# STM32GBK1CBT6 register map
File version: 1.6
CPU: CM4 r0p1, little endian, MPU, FPU, 4 interrupt priority bits
Registers are 32-bit, read-write, reset 0x0 unless marked. A register's access mark holds for its fields unless they carry their own. Offsets are from the block's base; [hi:lo] are bit positions; {n}, {i} and the like mark numbered series.

## RCC — Reset and clock control
Base 0x40021000
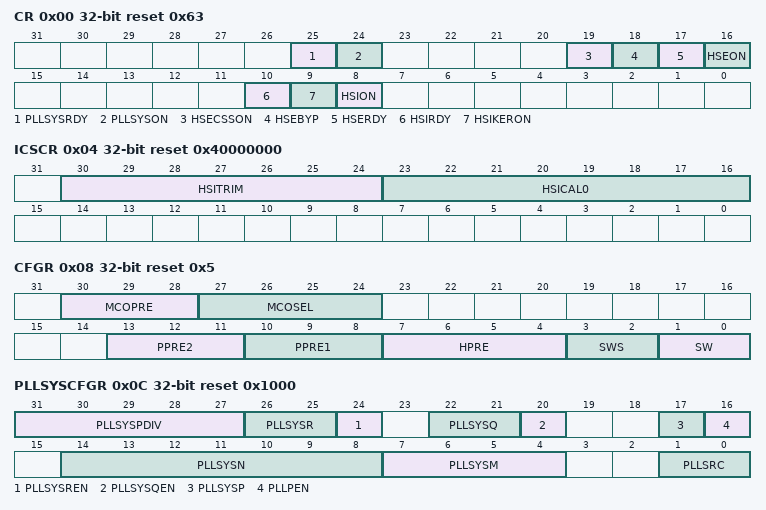
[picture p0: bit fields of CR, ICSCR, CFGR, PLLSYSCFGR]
0x00 CR access per field reset 0x63 — Clock control register
  [25] PLLSYSRDY ro — Main PLL clock ready flag
  [24] PLLSYSON rw — Main PLL enable
  [19] HSECSSON wo — Clock security system enable
  [18] HSEBYP rw — HSE crystal oscillator bypass
  [17] HSERDY ro — HSE clock ready flag
  [16] HSEON rw — HSE clock enable
  [10] HSIRDY ro — HSI clock ready flag
  [9] HSIKERON rw — HSI always enable for peripheral kernels
  [8] HSION rw — HSI clock enable
0x04 ICSCR access per field reset 0x40000000 — Internal clock sources calibration register
  [30:24] HSITRIM rw — Internal High Speed clock trimming
  [23:16] HSICAL0 ro — Internal High Speed clock Calibration
0x08 CFGR access per field reset 0x5 — Clock configuration register
  [30:28] MCOPRE rw — Microcontroller clock output prescaler
  [27:24] MCOSEL rw — Microcontroller clock output
  [13:11] PPRE2 rw — APB high-speed prescaler (APB2)
  [10:8] PPRE1 rw — PB low-speed prescaler (APB1)
  [7:4] HPRE rw — AHB prescaler
  [3:2] SWS ro — System clock switch status
  [1:0] SW rw — System clock switch
0x0C PLLSYSCFGR reset 0x1000 — PLL configuration register
  [31:27] PLLSYSPDIV — Main PLL division factor for PLLSAI2CLK
  [26:25] PLLSYSR — Main PLL division factor for PLLCLK (system clock)
  [24] PLLSYSREN — Main PLL PLLCLK output enable
  [22:21] PLLSYSQ — Main PLL division factor for PLLUSB1CLK(48 MHz clock)
  [20] PLLSYSQEN — Main PLL PLLUSB1CLK output enable
  [17] PLLSYSP — Main PLL division factor for PLLSAI3CLK (SAI1 and SAI2 clock)
  [16] PLLPEN — Main PLL PLLSAI3CLK output enable
  [14:8] PLLSYSN — Main PLL multiplication factor for VCO
  [7:4] PLLSYSM — Division factor for the main PLL and audio PLL (PLLSAI1 and PLLSAI2) input clock
  [1:0] PLLSRC — Main PLL, PLLSAI1 and PLLSAI2 entry clock source
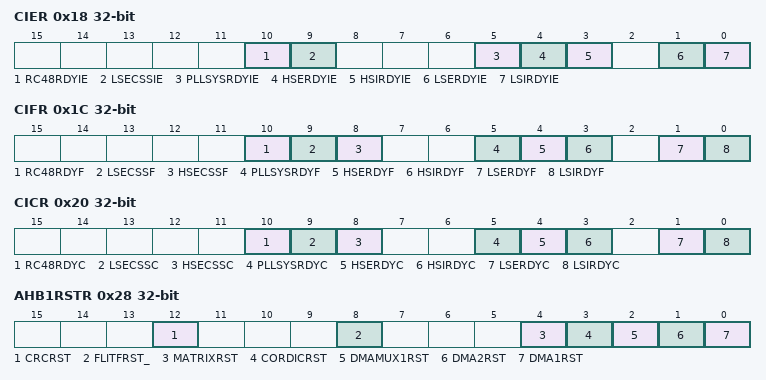
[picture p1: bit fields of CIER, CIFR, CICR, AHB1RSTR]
0x18 CIER — Clock interrupt enable register
  [10] RC48RDYIE — HSI48 ready interrupt enable
  [9] LSECSSIE — LSE clock security system interrupt enable
  [5] PLLSYSRDYIE — PLL ready interrupt enable
  [4] HSERDYIE — HSE ready interrupt enable
  [3] HSIRDYIE — HSI ready interrupt enable
  [1] LSERDYIE — LSE ready interrupt enable
  [0] LSIRDYIE — LSI ready interrupt enable
0x1C CIFR ro — Clock interrupt flag register
  [10] RC48RDYF — HSI48 ready interrupt flag
  [9] LSECSSF — LSE Clock security system interrupt flag
  [8] HSECSSF — Clock security system interrupt flag
  [5] PLLSYSRDYF — PLL ready interrupt flag
  [4] HSERDYF — HSE ready interrupt flag
  [3] HSIRDYF — HSI ready interrupt flag
  [1] LSERDYF — LSE ready interrupt flag
  [0] LSIRDYF — LSI ready interrupt flag
0x20 CICR wo — Clock interrupt clear register
  [10] RC48RDYC — HSI48 oscillator ready interrupt clear
  [9] LSECSSC — LSE Clock security system interrupt clear
  [8] HSECSSC — Clock security system interrupt clear
  [5] PLLSYSRDYC — PLL ready interrupt clear
  [4] HSERDYC — HSE ready interrupt clear
  [3] HSIRDYC — HSI ready interrupt clear
  [1] LSERDYC — LSE ready interrupt clear
  [0] LSIRDYC — LSI ready interrupt clear
0x28 AHB1RSTR — AHB1 peripheral reset register
  [12] CRCRST — CRC reset
  [8] FLITFRST_ — FLITF reset
  [4] MATRIXRST — MATRIX reset
  [3] CORDICRST — CORDIC reset
  [2] DMAMUX1RST — DMAMUXRST
  [1] DMA2RST — DMA2 reset
  [0] DMA1RST — DMA1 reset
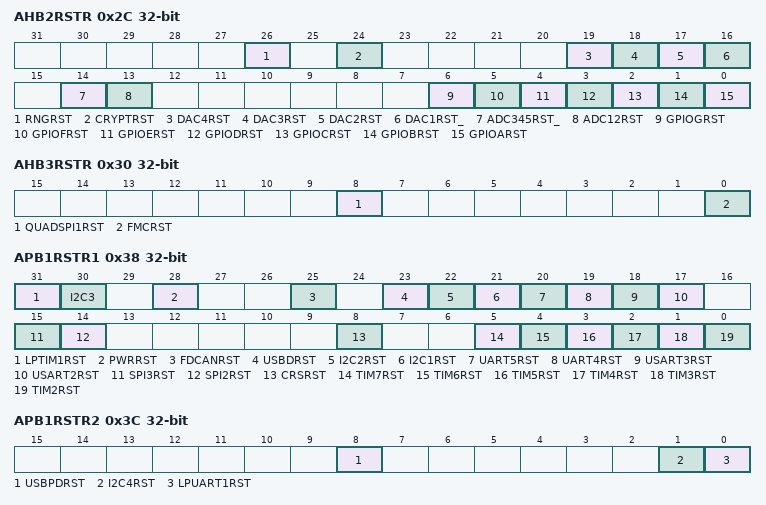
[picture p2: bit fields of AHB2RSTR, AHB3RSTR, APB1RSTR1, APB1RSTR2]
0x2C AHB2RSTR — AHB2 peripheral reset register
  [26] RNGRST — Random Number Generator module reset
  [24] CRYPTRST — Cryptography module reset
  [19] DAC4RST — DAC4 interface reset
  [18] DAC3RST — DAC3 interface reset
  [17] DAC2RST — DAC2 interface reset
  [16] DAC1RST_ — DAC1 interface reset
  [14] ADC345RST_ — SAR ADC345 interface reset
  [13] ADC12RST — ADC reset
  [6] GPIOGRST — IO port G reset
  [5] GPIOFRST — IO port F reset
  [4] GPIOERST — IO port E reset
  [3] GPIODRST — IO port D reset
  [2] GPIOCRST — IO port C reset
  [1] GPIOBRST — IO port B reset
  [0] GPIOARST — IO port A reset
0x30 AHB3RSTR — AHB3 peripheral reset register
  [8] QUADSPI1RST — Quad SPI 1 module reset
  [0] FMCRST — Flexible memory controller reset
0x38 APB1RSTR1 — APB1 peripheral reset register 1
  [31] LPTIM1RST — Low Power Timer 1 reset
  [30] I2C3 — I2C3 interface reset
  [28] PWRRST — Power interface reset
  [25] FDCANRST — FDCAN reset
  [23] USBDRST — USBD reset
  [22] I2C2RST — I2C2 reset
  [21] I2C1RST — I2C1 reset
  [20] UART5RST — UART5 reset
  [19] UART4RST — UART4 reset
  [18] USART3RST — USART3 reset
  [17] USART2RST — USART2 reset
  [15] SPI3RST — SPI3 reset
  [14] SPI2RST — SPI2 reset
  [8] CRSRST — Clock recovery system reset
  [5] TIM7RST — TIM7 timer reset
  [4] TIM6RST — TIM6 timer reset
  [3] TIM5RST — TIM5 timer reset
  [2] TIM4RST — TIM3 timer reset
  [1] TIM3RST — TIM3 timer reset
  [0] TIM2RST — TIM2 timer reset
0x3C APB1RSTR2 — APB1 peripheral reset register 2
  [8] USBPDRST — USBPD reset
  [1] I2C4RST — I2C4 reset
  [0] LPUART1RST — Low-power UART 1 reset
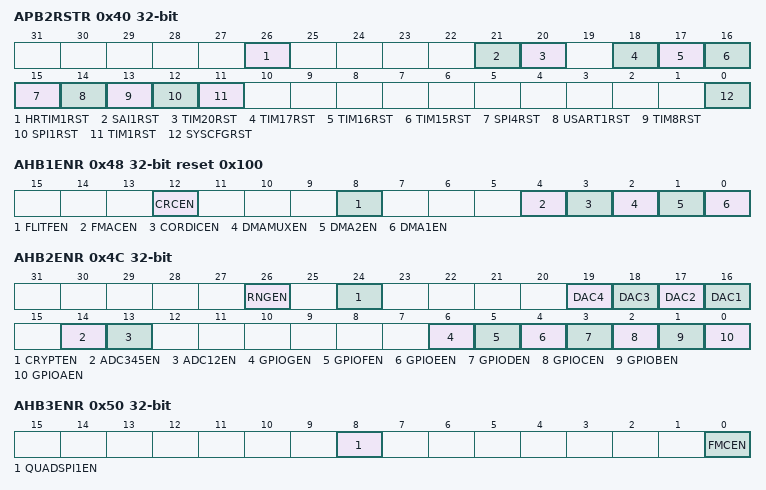
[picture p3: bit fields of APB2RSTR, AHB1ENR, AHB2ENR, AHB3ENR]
0x40 APB2RSTR — APB2 peripheral reset register
  [26] HRTIM1RST — HRTIMER reset
  [21] SAI1RST — Serial audio interface 1 (SAI1) reset
  [20] TIM20RST — Timer 20 reset
  [18] TIM17RST — TIM17 timer reset
  [17] TIM16RST — TIM16 timer reset
  [16] TIM15RST — TIM15 timer reset
  [15] SPI4RST — SPI 4 reset
  [14] USART1RST — USART1 reset
  [13] TIM8RST — TIM8 timer reset
  [12] SPI1RST — SPI1 reset
  [11] TIM1RST — TIM1 timer reset
  [0] SYSCFGRST — System configuration (SYSCFG) reset
0x48 AHB1ENR reset 0x100 — AHB1 peripheral clock enable register
  [12] CRCEN — CRC clock enable
  [8] FLITFEN — FLITF clock enable
  [4] FMACEN — FMAC clock enable
  [3] CORDICEN — CORDIC clock enable
  [2] DMAMUXEN — DMAMUX clock enable
  [1] DMA2EN — DMA2 clock enable
  [0] DMA1EN — DMA1 clock enable
0x4C AHB2ENR — AHB2 peripheral clock enable register
  [26] RNGEN — Random Number Generator clock enable
  [24] CRYPTEN — Cryptography clock enable
  [19] DAC4 — DAC4 clock enable
  [18] DAC3 — Random Number Generator clock enable
  [17] DAC2 — HASH clock enable
  [16] DAC1 — AES accelerator clock enable
  [14] ADC345EN — DCMI clock enable
  [13] ADC12EN — ADC clock enable
  [6] GPIOGEN — IO port G clock enable
  [5] GPIOFEN — IO port F clock enable
  [4] GPIOEEN — IO port E clock enable
  [3] GPIODEN — IO port D clock enable
  [2] GPIOCEN — IO port C clock enable
  [1] GPIOBEN — IO port B clock enable
  [0] GPIOAEN — IO port A clock enable
0x50 AHB3ENR — AHB3 peripheral clock enable register
  [8] QUADSPI1EN — Quad SPI 1 module clock enable
  [0] FMCEN — Flexible memory controller clock enable
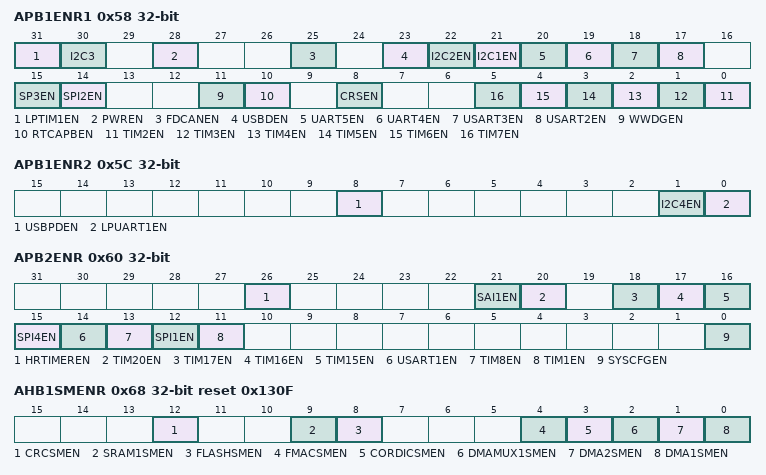
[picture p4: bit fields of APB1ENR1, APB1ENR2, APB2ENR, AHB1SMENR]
0x58 APB1ENR1
  [31] LPTIM1EN — Low power timer 1 clock enable
  [30] I2C3 — OPAMP interface clock enable
  [28] PWREN — Power interface clock enable
  [25] FDCANEN — FDCAN clock enable
  [23] USBDEN — USBDclock enable
  [22] I2C2EN — I2C2 clock enable
  [21] I2C1EN — I2C1 clock enable
  [20] UART5EN — UART5 clock enable
  [19] UART4EN — UART4 clock enable
  [18] USART3EN — USART3 clock enable
  [17] USART2EN — USART2 clock enable
  [15] SP3EN — SPI3 clock enable
  [14] SPI2EN — SPI2 clock enable
  [11] WWDGEN — Window watchdog clock enable
  [10] RTCAPBEN — RTC APB clock enable
  [8] CRSEN — CRSclock enable
  [n-2] TIM{n}EN (n=2..7) — TIM{n} timer clock enable
0x5C APB1ENR2 — APB1 peripheral clock enable register 2
  [8] USBPDEN — USBPD clock enable
  [1] I2C4EN — I2C4 clock enable
  [0] LPUART1EN — Low power UART 1 clock enable
0x60 APB2ENR
  [26] HRTIMEREN — HRTIMER clock enable
  [21] SAI1EN — SAI1 clock enable
  [20] TIM20EN — Timer 20 clock enable
  [18] TIM17EN — TIM17 timer clock enable
  [17] TIM16EN — TIM16 timer clock enable
  [16] TIM15EN — TIM15 timer clock enable
  [15] SPI4EN — SPI 4 clock enable
  [14] USART1EN — USART1clock enable
  [13] TIM8EN — TIM8 timer clock enable
  [12] SPI1EN — SPI1 clock enable
  [11] TIM1EN — TIM1 timer clock enable
  [0] SYSCFGEN — SYSCFG clock enable
0x68 AHB1SMENR reset 0x130F — AHB1 peripheral clocks enable in Sleep and Stop modes register
  [12] CRCSMEN
  [9] SRAM1SMEN — SRAM1 interface clocks enable during Sleep and Stop modes
  [8] FLASHSMEN — Flash memory interface clocks enable during Sleep and Stop modes
  [4] FMACSMEN — FMACSM clock enable
  [3] CORDICSMEN — CORDIC clock enable during sleep mode
  [2] DMAMUX1SMEN — DMAMUX clock enable during Sleep and Stop modes
  [1] DMA2SMEN — DMA2 clocks enable during Sleep and Stop modes
  [0] DMA1SMEN — DMA1 clocks enable during Sleep and Stop modes
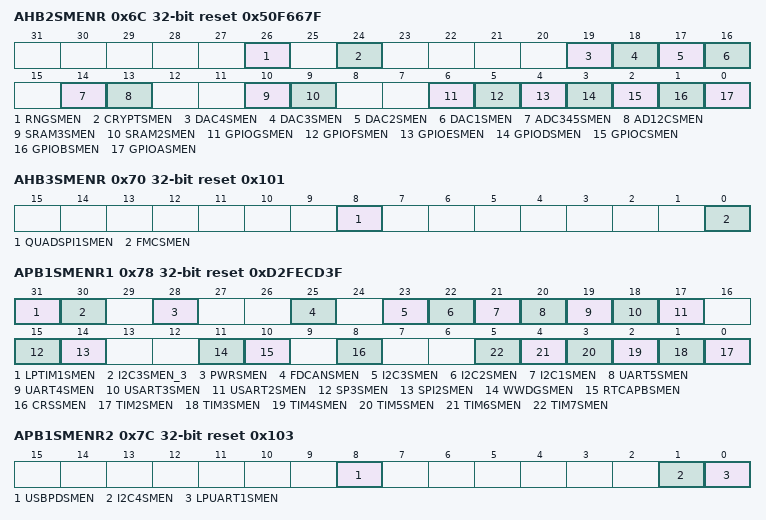
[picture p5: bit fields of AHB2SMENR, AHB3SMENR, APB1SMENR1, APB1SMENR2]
0x6C AHB2SMENR reset 0x50F667F — AHB2 peripheral clocks enable in Sleep and Stop modes register
  [26] RNGSMEN — Random Number Generator clock enable during sleep mode
  [24] CRYPTSMEN — Cryptography clock enable during sleep mode
  [19] DAC4SMEN — DAC4 clock enable during sleep mode
  [18] DAC3SMEN — DAC3 clock enable during sleep mode
  [17] DAC2SMEN — HASH clock enable during Sleep and Stop modes
  [16] DAC1SMEN — AES accelerator clocks enable during Sleep and Stop modes
  [14] ADC345SMEN — DCMI clock enable during Sleep and Stop modes
  [13] AD12CSMEN — ADC clocks enable during Sleep and Stop modes
  [10] SRAM3SMEN — SRAM2 interface clocks enable during Sleep and Stop modes
  [9] SRAM2SMEN — SRAM2 interface clocks enable during Sleep and Stop modes
  [6] GPIOGSMEN — IO port G clocks enable during Sleep and Stop modes
  [5] GPIOFSMEN — IO port F clocks enable during Sleep and Stop modes
  [4] GPIOESMEN — IO port E clocks enable during Sleep and Stop modes
  [3] GPIODSMEN — IO port D clocks enable during Sleep and Stop modes
  [2] GPIOCSMEN — IO port C clocks enable during Sleep and Stop modes
  [1] GPIOBSMEN — IO port B clocks enable during Sleep and Stop modes
  [0] GPIOASMEN — IO port A clocks enable during Sleep and Stop modes
0x70 AHB3SMENR reset 0x101 — AHB3 peripheral clocks enable in Sleep and Stop modes register
  [8] QUADSPI1SMEN — QUAD SPI 1 module clock enable during sleep mode
  [0] FMCSMEN — Flexible memory controller clocks enable during Sleep and Stop modes
0x78 APB1SMENR1 reset 0xD2FECD3F
  [31] LPTIM1SMEN — Low Power Timer1 clock enable during sleep mode
  [30] I2C3SMEN_3 — I2C 3 interface clock enable during sleep mode
  [28] PWRSMEN — Power interface clocks enable during Sleep and Stop modes
  [25] FDCANSMEN — FDCAN clock enable during sleep mode
  [23] I2C3SMEN — I2C3 clocks enable during Sleep and Stop modes
  [22] I2C2SMEN — I2C2 clocks enable during Sleep and Stop modes
  [21] I2C1SMEN — I2C1 clocks enable during Sleep and Stop modes
  [20] UART5SMEN — UART5 clocks enable during Sleep and Stop modes
  [19] UART4SMEN — UART4 clocks enable during Sleep and Stop modes
  [18] USART3SMEN — USART3 clocks enable during Sleep and Stop modes
  [17] USART2SMEN — USART2 clocks enable during Sleep and Stop modes
  [15] SP3SMEN — SPI3 clocks enable during Sleep and Stop modes
  [14] SPI2SMEN — SPI2 clocks enable during Sleep and Stop modes
  [11] WWDGSMEN — Window watchdog clocks enable during Sleep and Stop modes
  [10] RTCAPBSMEN — RTC APB clock enable during Sleep and Stop modes
  [8] CRSSMEN — CRS clock enable during sleep mode
  [n-2] TIM{n}SMEN (n=2..7) — TIM{n} timer clocks enable during Sleep and Stop modes
0x7C APB1SMENR2 reset 0x103 — APB1 peripheral clocks enable in Sleep and Stop modes register 2
  [8] USBPDSMEN — USB PD clock enable during sleep mode
  [1] I2C4SMEN — I2C4 clocks enable during Sleep and Stop modes
  [0] LPUART1SMEN — Low power UART 1 clocks enable during Sleep and Stop modes
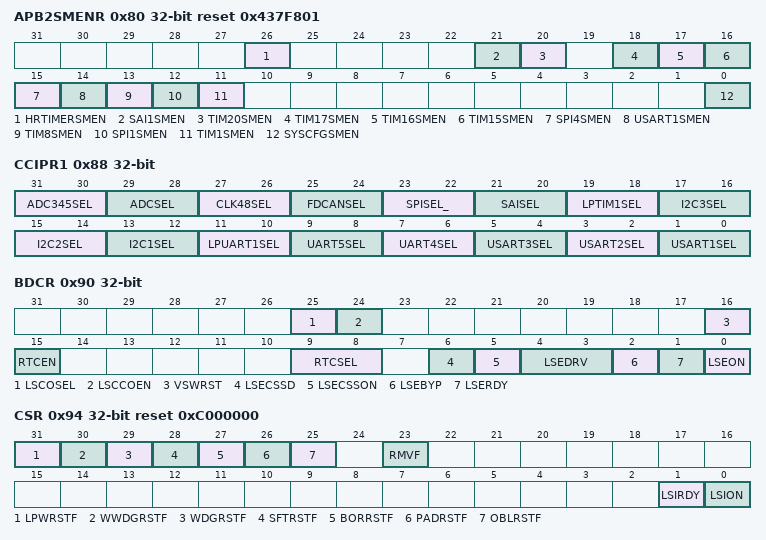
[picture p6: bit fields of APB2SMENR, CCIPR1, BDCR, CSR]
0x80 APB2SMENR reset 0x437F801
  [26] HRTIMERSMEN — HRTIMER clock enable during sleep mode
  [21] SAI1SMEN — SAI1 clock enable during sleep mode
  [20] TIM20SMEN — Timer 20clock enable during sleep mode
  [18] TIM17SMEN — TIM17 timer clocks enable during Sleep and Stop modes
  [17] TIM16SMEN — TIM16 timer clocks enable during Sleep and Stop modes
  [16] TIM15SMEN — TIM15 timer clocks enable during Sleep and Stop modes
  [15] SPI4SMEN — SPI4 timer clocks enable during Sleep and Stop modes
  [14] USART1SMEN — USART1clocks enable during Sleep and Stop modes
  [13] TIM8SMEN — TIM8 timer clocks enable during Sleep and Stop modes
  [12] SPI1SMEN — SPI1 clocks enable during Sleep and Stop modes
  [11] TIM1SMEN — TIM1 timer clocks enable during Sleep and Stop modes
  [0] SYSCFGSMEN — SYSCFG clocks enable during Sleep and Stop modes
0x88 CCIPR1 — CCIPR
  [31:30] ADC345SEL — ADC3/4/5 clock source selection
  [29:28] ADCSEL — ADCs clock source selection
  [27:26] CLK48SEL — 48 MHz clock source selection
  [25:24] FDCANSEL — SAI2 clock source selection
  [23:22] SPISEL_ — SAI1 clock source selection
  [21:20] SAISEL — Low power timer 2 clock source selection
  [19:18] LPTIM1SEL — Low power timer 1 clock source selection
  [17:16] I2C3SEL — I2C3 clock source selection
  [15:14] I2C2SEL — I2C2 clock source selection
  [13:12] I2C1SEL — I2C1 clock source selection
  [11:10] LPUART1SEL — LPUART1 clock source selection
  [9:8] UART5SEL — UART5 clock source selection
  [7:6] UART4SEL — UART4 clock source selection
  [5:4] USART3SEL — USART3 clock source selection
  [3:2] USART2SEL — USART2 clock source selection
  [1:0] USART1SEL — USART1 clock source selection
0x90 BDCR access per field
  [25] LSCOSEL rw — Low speed clock output selection
  [24] LSCCOEN rw — Low speed clock output enable
  [16] VSWRST rw — Vswitch domain software reset
  [15] RTCEN rw — RTC clock enable
  [9:8] RTCSEL rw — RTC clock source selection
  [6] LSECSSD ro
  [5] LSECSSON rw
  [4:3] LSEDRV rw — SE oscillator drive capability
  [2] LSEBYP rw — LSE oscillator bypass
  [1] LSERDY ro — LSE oscillator ready
  [0] LSEON rw — LSE oscillator enable
0x94 CSR access per field reset 0xC000000
  [31] LPWRSTF ro — Low-power reset flag
  [30] WWDGRSTF ro — Window watchdog reset flag
  [29] WDGRSTF ro — Independent window watchdog reset flag
  [28] SFTRSTF ro — Software reset flag
  [27] BORRSTF ro — BOR flag
  [26] PADRSTF ro — Pad reset flag
  [25] OBLRSTF ro — Option byte loader reset flag
  [23] RMVF rw — Remove reset flag
  [1] LSIRDY ro — LSI oscillator ready
  [0] LSION rw — LSI oscillator enable
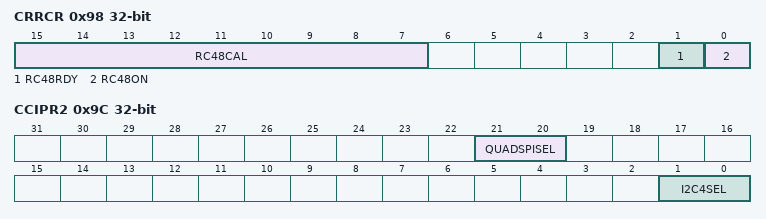
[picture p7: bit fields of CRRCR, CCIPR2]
0x98 CRRCR access per field — Clock recovery RC register
  [15:7] RC48CAL ro — HSI48 clock calibration
  [1] RC48RDY ro — HSI48 clock ready flag
  [0] RC48ON rw — HSI48 clock enable
0x9C CCIPR2 — Peripherals independent clock configuration register
  [21:20] QUADSPISEL — Octospi clock source selection
  [1:0] I2C4SEL — I2C4 clock source selection

## Notices in the file
Copyright (c) 2020 STMicroelectronics.
SPDX-License-Identifier: Apache-2.0
Licensed under the Apache License, Version 2.0 (the "License");
you may not use this file except in compliance with the License.
You may obtain a copy of the License at
http://www.apache.org/licenses/LICENSE-2.0
Unless required by applicable law or agreed to in writing, software
distributed under the License is distributed on an "AS IS" BASIS,
WITHOUT WARRANTIES OR CONDITIONS OF ANY KIND, either express or implied.
See the License for the specific language governing permissions and
limitations under the License.
